# STM32F091CBT6 register map
File version: 1.0
STM32F091CBT6,STM32F091CBT7,STM32F091CBU6,STM32F091CBU7,STM32F091CCT6,STM32F091CCT7,STM32F091CCU6,STM32F091CCU7,STM32F091RBT6,STM32F091RCH6,STM32F091RCH7,STM32F091RCT6,STM32F091RCT7,STM32F091RCY6,STM32F091RCY7,STM32F091VBT6,STM32F091VBT7,STM32F091VCH6,STM32F091VCH7,STM32F091VCT6,STM32F091VCT7,STM32F098CCT6,STM32F098CCT7,STM32F098CCU6,STM32F098CCU7,STM32F098RCH6,STM32F098RCT6,STM32F098RCY6,STM32F098VCH6,STM32F098VCT6
Registers are 32-bit, access not given, reset 0x0 unless marked. A register's access mark holds for its fields unless they carry their own. Offsets are from the block's base; lines under a group give offsets from that group; [hi:lo] are bit positions; {n}, {i} and the like mark numbered series; 'fields as' and 'values as' point back to an identical list; <NAME> marks a mode.

## Memory map
0x40000000 TIM2
0x40000400 TIM3
0x40001000 TIM6
0x40001400 TIM7
0x40002000 TIM14
0x40002800 RTC
0x40002C00 WWDG
0x40003000 IWDG
0x40003800 SPI2
0x40004400 USART2
0x40004800 USART3
0x40004C00 USART4
0x40005000 USART5
0x40005400 I2C1
0x40005800 I2C2
0x40005C00 USB
0x40006000 USB
0x40006000 CANSRAM
0x40006400 CAN
0x40006C00 CRS
0x40007000 PWR
0x40007400 DAC
0x40007800 CEC
0x40010000 SYSCFGCOMP
0x40010400 EXTI
0x40011400 USART6
0x40011800 USART7
0x40011C00 USART8
0x40012400 ADC
0x40012C00 TIM1
0x40013000 SPI1
0x40013800 USART1
0x40014000 TIM15
0x40014400 TIM16
0x40014800 TIM17
0x40015800 DBGMCU
0x40021000 RCC
0x40022000 FLASH
0x40023000 CRC
0x40024000 TSC
0x48000000 GPIOA
0x48000400 GPIOB
0x48000800 GPIOC
0x48000C00 GPIOD
0x48001000 GPIOE
0x48001400 GPIOF

## TIM2
Base 0x40000000
Same registers: TIM3 0x40000400
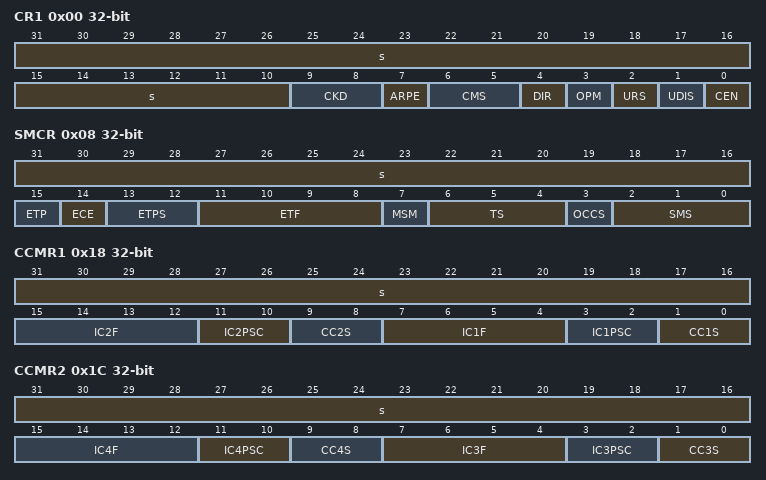
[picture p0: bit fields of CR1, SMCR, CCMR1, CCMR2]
0x00 CR1
  [31:10] s, [9:8] CKD, [7] ARPE, [6:5] CMS, [4] DIR, [3] OPM, [2] URS, [1] UDIS, [0] CEN
0x04 CR2
  [7] TI1S, [6:4] MMS, [3] CCDS, [31:0] s
0x08 SMCR
  [31:16] s, [15] ETP, [14] ECE, [13:12] ETPS, [11:8] ETF, [7] MSM, [6:4] TS, [3] OCCS, [2:0] SMS
0x0C DIER
  [14] TDE, [n+8] CC{n}DE (n=1..4), [8] UDE, [6] TIE, [31:5] s, [n] CC{n}IE (n=1..4), [0] UIE
0x10 SR
  [n+8] CC{n}OF (n=1..4), [6] TIF, [31:5] s, [n] CC{n}IF (n=1..4), [0] UIF
0x14 EGR
  [6] TG, [31:5] s, [n] CC{n}G (n=1..4), [0] UG
0x18 CCMR1
  [31:16] s, [15:12] IC2F, [11:10] IC2PSC, [9:8] CC2S, [7:4] IC1F, [3:2] IC1PSC, [1:0] CC1S
0x1C CCMR2
  [31:16] s, [15:12] IC4F, [11:10] IC4PSC, [9:8] CC4S, [7:4] IC3F, [3:2] IC3PSC, [1:0] CC3S
0x20 CCER
  [4n-1] CC{n}NP (n=1..4), [4n-3] CC{n}P (n=1..4), [4n-4] CC{n}E (n=1..4), [31:2] s
0x24 CNT
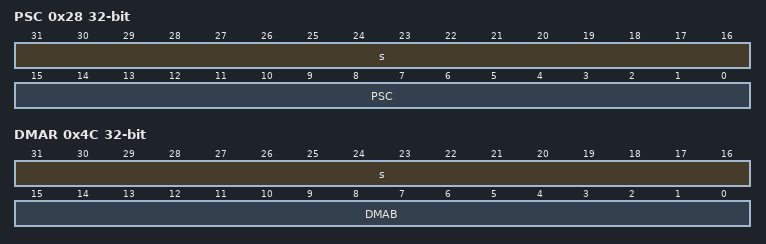
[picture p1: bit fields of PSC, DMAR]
0x28 PSC
  [31:16] s, [15:0] PSC
0x2C ARR
{0x30+4i} CCR{i} (i=1..4)
0x48 DCR
  [12:8] DBL, [31:5] s, [4:0] DBA
0x4C DMAR
  [31:16] s, [15:0] DMAB

## TIM6
Base 0x40001000
Same registers: TIM7 0x40001400
0x00 CR1
  [7] ARPE, [31:4] s, [3] OPM, [2] URS, [1] UDIS, [0] CEN
0x04 CR2
  [6:4] MMS, [31:0] s
0x0C DIER
  [8] UDE, [31:1] s, [0] UIE
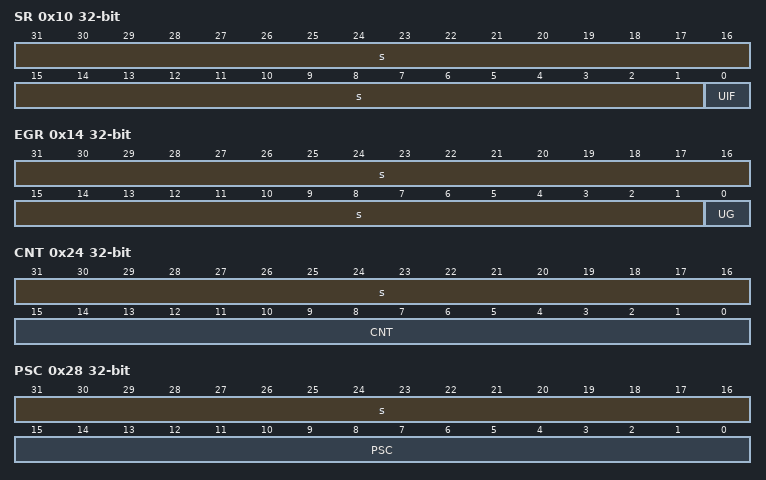
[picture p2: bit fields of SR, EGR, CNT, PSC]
0x10 SR
  [31:1] s, [0] UIF
0x14 EGR
  [31:1] s, [0] UG
0x24 CNT
  [31:16] s, [15:0] CNT
0x28 PSC
  [31:16] s, [15:0] PSC
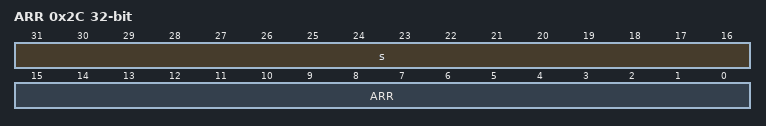
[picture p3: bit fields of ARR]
0x2C ARR
  [31:16] s, [15:0] ARR

## TIM14
Base 0x40002000
0x00 CR1
  [9:8] CKD, [7] ARPE, [31:3] s, [2] URS, [1] UDIS, [0] CEN
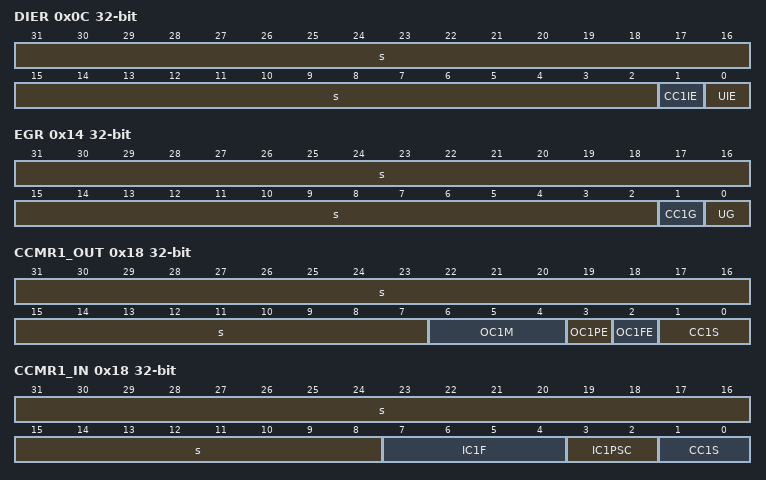
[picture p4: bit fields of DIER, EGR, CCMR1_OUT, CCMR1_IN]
0x0C DIER
  [31:2] s, [1] CC1IE, [0] UIE
0x10 SR
  [9] CC1OF, [31:2] s, [1] CC1IF, [0] UIF
0x14 EGR
  [31:2] s, [1] CC1G, [0] UG
0x18 CCMR1_OUT
  [31:7] s, [6:4] OC1M, [3] OC1PE, [2] OC1FE, [1:0] CC1S
0x18 CCMR1_IN
  [31:8] s, [7:4] IC1F, [3:2] IC1PSC, [1:0] CC1S
0x20 CCER
  [3] CC1NP, [31:2] s, [1] CC1P, [0] CC1E
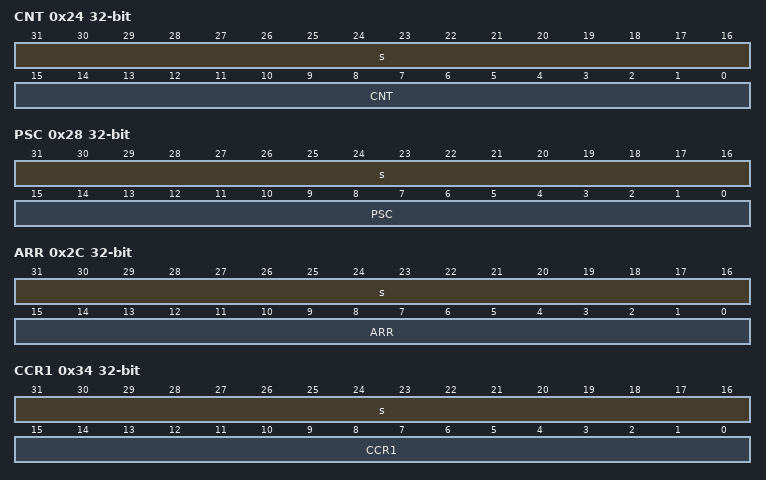
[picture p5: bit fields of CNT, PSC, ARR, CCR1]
0x24 CNT
  [31:16] s, [15:0] CNT
0x28 PSC
  [31:16] s, [15:0] PSC
0x2C ARR
  [31:16] s, [15:0] ARR
0x34 CCR1
  [31:16] s, [15:0] CCR1
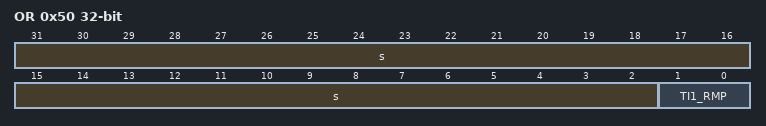
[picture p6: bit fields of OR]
0x50 OR
  [31:2] s, [1:0] TI1_RMP

## RTC
Base 0x40002800
0x00 TR
  [22] PM, [21:20] HT, [19:16] HU, [14:12] MNT, [11:8] MNU, [31:7] s, [6:4] ST, [3:0] SU
0x04 DR
  [23:20] YT, [19:16] YU, [15:13] WDU, [12] MT, [11:8] MU, [31:6] s, [5:4] DT, [3:0] DU
0x08 CR
  [23] COE, [22:21] OSEL, [20] POL, [19] COSEL, [18] BKP, [17] SUB1H, [16] ADD1H, [15] TSIE, [14] WUTIE, [12] ALRAIE, [11] TSE, [10] WUTE, [8] ALRAE, [31:7] s, [6] FMT, [5] BYPSHAD, [4] REFCKON, [3] TSEDGE, [2:0] WUCKSEL
0x0C ISR
  [16] RECALPF, [15] TAMP3F, [14] TAMP2F, [13] TAMP1F, [12] TSOVF, [11] TSF, [10] WUTF, [8] ALRAF, [7] INIT, [6] INITF, [5] RSF, [4] INITS, [3] SHPF, [2] WUTWF, [31:1] s, [0] ALRAWF
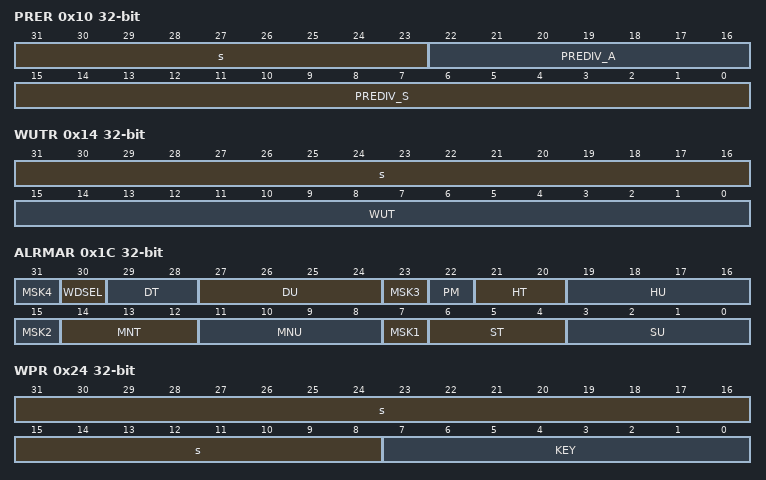
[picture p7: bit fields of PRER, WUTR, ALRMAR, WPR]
0x10 PRER
  [31:23] s, [22:16] PREDIV_A, [15:0] PREDIV_S
0x14 WUTR
  [31:16] s, [15:0] WUT
0x1C ALRMAR
  [8n-1] MSK{n} (n=1..4), [30] WDSEL, [29:28] DT, [27:24] DU, [22] PM, [21:20] HT, [19:16] HU, [14:12] MNT, [11:8] MNU, [6:4] ST, [3:0] SU
0x24 WPR
  [31:8] s, [7:0] KEY
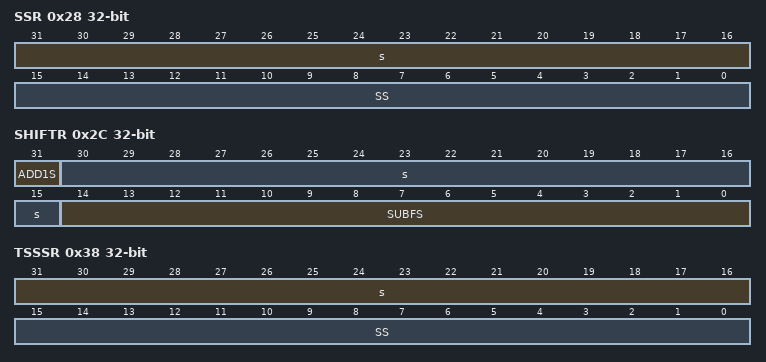
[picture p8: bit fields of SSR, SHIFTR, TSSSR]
0x28 SSR
  [31:16] s, [15:0] SS
0x2C SHIFTR
  [31] ADD1S, [30:15] s, [14:0] SUBFS
0x30 TSTR
  fields as TR
0x34 TSDR
  [15:13] WDU, [12] MT, [11:8] MU, [31:6] s, [5:4] DT, [3:0] DU
0x38 TSSSR
  [31:16] s, [15:0] SS
0x3C CALR
  [15] CALP, [14] CALW8, [13] CALW16, [31:9] s, [8:0] CALM
0x40 TAFCR
  [23:22] PC15MODE, [21] PC14VALUE, [20] PC14MODE, [19:18] PC13VALUE, [31:16] s, [15] TAMPPUDIS, [14:13] TAMPPRCH, [12:11] TAMPFLT, [10:8] TAMPFREQ, [7] TAMPTS, [6] TAMP3TRG, [5] TAMP3E, [4] TAMP2TRG, [3] TAMP2E, [2] TAMPIE, [1] TAMP1TRG, [0] TAMP1E
0x44 ALRMASSR
  [27:24] MASKSS, [31:15] s, [14:0] SS
{0x50+4i} BKP{i}R (i=0..4)
  [31:0] BKP
